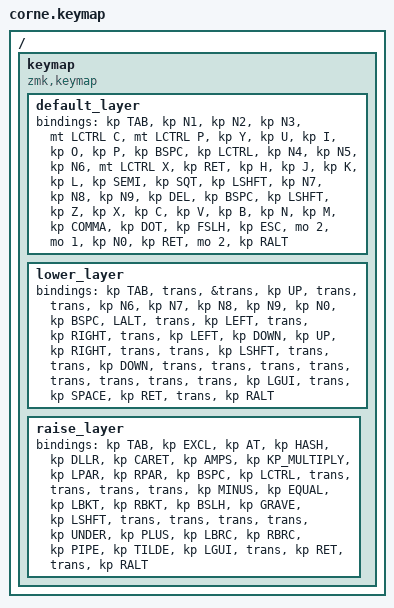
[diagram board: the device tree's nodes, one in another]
/*
 * Copyright (c) 2020 The ZMK Contributors
 *
 * SPDX-License-Identifier: MIT
 */

#include <behaviors.dtsi>
#include <dt-bindings/zmk/keys.h>
#include <dt-bindings/zmk/bt.h>

/ {
        keymap {
                compatible = "zmk,keymap";

                default_layer {
// --------------------------------------
// | TAB  |  1  |  2  |  3  |  Copy    |  Paste      |
// | CTRL |  4  |  5  |  6  |  Cut     |  Enter      |
// | SHFT |  7  |  8  |  9  |  Delete  |  Backspace  |
//                    | RSE | LWR | 0  |
                        bindings = <
   &kp TAB   &kp N1 &kp N2 &kp N3 &mt LCTRL C &mt LCTRL P &kp Y &kp U  &kp I     &kp O   &kp P    &kp BSPC
   &kp LCTRL &kp N4 &kp N5 &kp N6 &mt LCTRL X &kp RET &kp H &kp J  &kp K     &kp L   &kp SEMI &kp SQT
   &kp LSHFT &kp N7 &kp N8 &kp N9 &kp DEL &kp BSPC &kp LSHFT &kp Z &kp X &kp C &kp V &kp B   &kp N &kp M  &kp COMMA &kp DOT &kp FSLH &kp ESC
                  &mo 2 &mo 1 &kp N0 &kp RET &mo 2 &kp RALT
                        >;
                };
                lower_layer {
// --------------------------------------
// | TAB  |    |    |  UP |     |     |
// | ALT  |    | LFT|     | RHT |     |
// | SHFT |    |    | DWN |     |     |
//                    | GUI |     | SPC |
                        bindings = <
   &kp TAB     &trans       &&trans       &kp UP       &trans       &trans      &kp N6   &kp N7   &kp N8 &kp N9    &kp N0 &kp BSPC
   &LALT &trans &kp LEFT &trans &kp RIGHT &trans       &kp LEFT &kp DOWN &kp UP &kp RIGHT &trans &trans
   &kp LSHFT  &trans       &trans       &kp DOWN       &trans       &trans      &trans   &trans   &trans &trans    &trans &trans
                                    &kp LGUI     &trans       &kp SPACE      &kp RET  &trans   &kp RALT
                        >;
                };

                raise_layer {
// -----------------------------------------------------------------------------------------
// |  TAB |  !  |  @  |  #  |  $  |  %  |
// | CTRL |     |     |     |     |     |
// | SHFT |     |     |     |     |     |
//                    | GUI |     | SPC |
                        bindings = <
   &kp  TAB  &kp EXCL &kp AT &kp HASH &kp DLLR  &kp CARET &kp AMPS  &kp KP_MULTIPLY &kp LPAR &kp RPAR &kp BSPC
   &kp LCTRL &trans   &trans &trans   &trans    &kp MINUS &kp EQUAL &kp LBKT        &kp RBKT &kp BSLH &kp GRAVE
   &kp LSHFT &trans   &trans &trans   &trans    &kp UNDER &kp PLUS  &kp LBRC        &kp RBRC &kp PIPE &kp TILDE
                             &kp LGUI &trans    &kp RET   &trans    &kp RALT
                        >;
                };
        };
};
